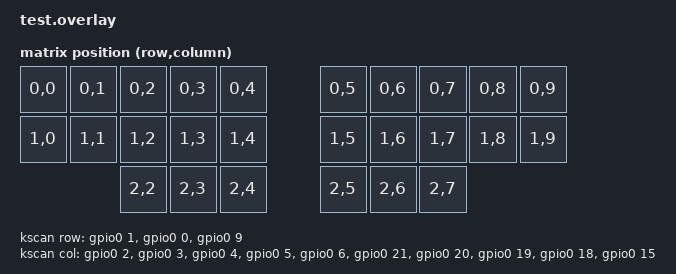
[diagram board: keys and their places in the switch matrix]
// This file was generated from a template. Edit it to match your keyboard.
// See https://zmk.dev/docs/development/hardware-integration/new-shield for more
// instructions.

#include <dt-bindings/zmk/matrix_transform.h>

#include "test-layouts.dtsi"

/ {
    chosen {
        zmk,physical-layout = &default_layout;
    };

    kscan: kscan {
        // If the hardware does not use a switch matrix, change this to the
        // appropriate driver and update the properties below to match.
        // See https://zmk.dev/docs/config/kscan for supported key scan drivers.
        compatible = "zmk,kscan-gpio-matrix";
        // Set this to "col2row" or "row2col" to match the hardware. If using
        // "row2col", change the col-gpios to (GPIO_ACTIVE_HIGH | GPIO_PULL_DOWN)
        // and the row-gpios to GPIO_ACTIVE_HIGH.
        diode-direction = "row2col";
        wakeup-source;

        // Replace these comments with the GPIO pins in the matrix.
        // See https://zmk.dev/docs/development/hardware-integration/new-shield#shield-overlays
        col-gpios
            = <&gpio0 2 (GPIO_ACTIVE_HIGH | GPIO_PULL_DOWN)>
            , <&gpio0 3 (GPIO_ACTIVE_HIGH| GPIO_PULL_DOWN)>
            , <&gpio0 4 (GPIO_ACTIVE_HIGH| GPIO_PULL_DOWN)>
            , <&gpio0 5 (GPIO_ACTIVE_HIGH| GPIO_PULL_DOWN)>
            , <&gpio0 6 (GPIO_ACTIVE_HIGH| GPIO_PULL_DOWN)>
            , <&gpio0 21 (GPIO_ACTIVE_HIGH| GPIO_PULL_DOWN)>
            , <&gpio0 20 (GPIO_ACTIVE_HIGH| GPIO_PULL_DOWN)>
            , <&gpio0 19 (GPIO_ACTIVE_HIGH| GPIO_PULL_DOWN)>
            , <&gpio0 18 (GPIO_ACTIVE_HIGH| GPIO_PULL_DOWN)>
            , <&gpio0 15 (GPIO_ACTIVE_HIGH| GPIO_PULL_DOWN)>
            ;

        row-gpios
            = <&gpio0 1 GPIO_ACTIVE_HIGH>
            , <&gpio0 0 GPIO_ACTIVE_HIGH>
            , <&gpio0 9 GPIO_ACTIVE_HIGH>
            ;
    };

    default_transform: default_transform {
        // See https://zmk.dev/docs/development/hardware-integration/new-shield#matrix-transform
        // for how to configure this
        compatible = "zmk,matrix-transform";
        columns = <10>;
        rows = <3>;

        map = <
            RC(0,0) RC(0,1) RC(0,2) RC(0,3) RC(0,4) RC(0,5) RC(0,6) RC(0,7) RC(0,8) RC(0,9)
            RC(1,0) RC(1,1) RC(1,2) RC(1,3) RC(1,4) RC(1,5) RC(1,6) RC(1,7) RC(1,8) RC(1,9)
                            RC(2,2) RC(2,3) RC(2,4) RC(2,5) RC(2,6) RC(2,7)
        >;
    };
};
